# H6 register map
Vendor: Allwinner; Series: H6; File version: 0.1
CPU: CA53 0, little endian, MPU, no FPU, 0 interrupt priority bits
Registers are 32-bit, read-write, reset 0x0 unless marked. A register's access mark holds for its fields unless they carry their own. Offsets are from the block's base; [hi:lo] are bit positions; {n}, {i} and the like mark numbered series.

## OWA
Base 0x05093000
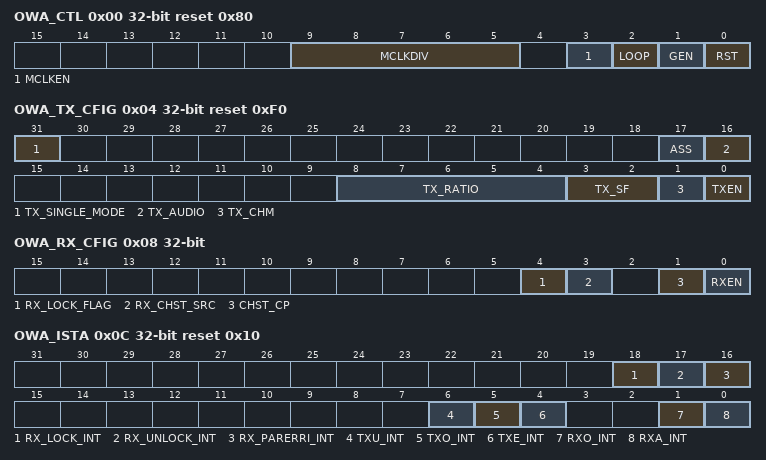
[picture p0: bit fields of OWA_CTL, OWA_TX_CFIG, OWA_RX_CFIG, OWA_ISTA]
0x00 OWA_CTL reset 0x80
  [9:5] MCLKDIV — MCLK Clock Divide Ratio MCLK Divide Ratio from PLL_AUDIO 00000: Divide by 128 00001: Divide by 2 00010: Divide by 4 00011: Divide by 6 00100: Divide by 8 00101: Divide by 10 00110: Divide by 12 00111: Divide by 14 01000: Divide by 16 01001: Divide by 18 01010: Divide by 20 01011: Divide by 22 01100: Divide by 24 ......... 11111: Divide by 62
    0=Divide_by_128; 1=Divide_by_2; 2=Divide_by_4; 3=Divide_by_6; 4=Divide_by_8; 5=Divide_by_10; 6=Divide_by_12; 7=Divide_by_14; 8=Divide_by_16; 9=Divide_by_18; 10=Divide_by_20; 11=Divide_by_22; 12=Divide_by_24; 31=Divide_by_62
  [3] MCLKEN — MCLK Enable 0: Disable 1: Enable
    0=Disable; 1=Enable
  [2] LOOP — Loop Back Test 0: Normal Mode 1: Loop Back Test When set `1`, connecting the DOUT with the DIN.
    0=Normal Mode; 1=Loop Back Test When set `1`, connecting the DOUT with the DIN
  [1] GEN — Global Enable A disable on this bit overrides any other block or channel enables and flushes all FIFOs. 0: Disable 1: Enable
    0=Disable; 1=Enable
  [0] RST — Reset 0: Normal 1: Reset Self clear to 0.
    0=Normal; 1=Reset Self clear to 0
0x04 OWA_TX_CFIG reset 0xF0 — OWA TX Configuration Register
  [31] TX_SINGLE_MODE — Tx Single Channel Mode 0: Disable 1: Enable
    0=Disable; 1=Enable
  [17] ASS — Audio Sample Select with TX FIFO Underrun When 0: Sending 0 1: Sending the last audio This bit is only valid in PCM mode
    0=Sending_0; 1=Sending the last audio This bit is only valid in PCM mode
  [16] TX_AUDIO — TX Data Type 0: Linear PCM (Valid bit of both sub-frame set to 0 ) 1: Non-audio(Valid bit of both sub-frame set to 1)
    0=Linear PCM (Valid bit of both sub-frame set to 0 ); 1=non_audio_openingparen_Valid_bit (Non-audio(Valid bit of both sub-frame set to 1))
  [8:4] TX_RATIO — TX Clock Divide Ratio Clock divide ratio = TX TATIO +1 Fs= PLL_AUDIO/[(TX_TATIO +1)*64*2]
  [3:2] TX_SF — TX Sample Format 00: 16 bits 01: 20 bits 10: 24 bits 11: Reserved
    0=_16_bits; 1=_20_bits; 2=_24_bits
  [1] TX_CHM — CHSTMODE 0: Channel status A&B set to 0 1: Channel status A&B generated form TX_CHSTA
    0=Channel_status_A_amp_B_set (Channel status A&B set to 0); 1=Channel_status_A_amp_B_generated (Channel status A&B generated form TX_CHSTA)
  [0] TXEN — 0: Disabled 1: Enabled
    0=Disabled; 1=Enabled
0x08 OWA_RX_CFIG — OWA RX Configuration Register
  [4] RX_LOCK_FLAG ro — 0: Unlock 1: Lock
    0=Unlock; 1=Lock
  [3] RX_CHST_SRC — 0: RX_CH_STA Register Holds Status from Channel A 1: RX_CH_STA Register Holds Status from Channel B
    0=RX_CH_STA_Register_Holds_Status_from_Channel_A; 1=RX_CH_STA_Register_Holds_Status_from_Channel_B
  [1] CHST_CP — Channel Status Capture 0: Idle or Capture End 1: Capture Channel Status Start When set to `1`, the channel status information is capturing, the bit will clear to `0` after captured.
    0=Idle or Capture End; 1=Capture Channel Status Start When set to `1`, the channel status information is capturing, the bit will clear to `0` after captured
  [0] RXEN — 0: Disabled 1: Enabled
    0=Disabled; 1=Enabled
0x0C OWA_ISTA reset 0x10 — OWA Interrupt Status Register
  [18] RX_LOCK_INT write-1-clears — 0: No Pending IRQ 1: RX lock Pending Interrupt (RX_LOCK_FLAG 0→1) Write `1` to clear this interrupt.
    0=No Pending IRQ; 1=RX (RX lock Pending Interrupt (RX_LOCK_FLAG 0→1) Write `1` to clear this interrupt.)
  [17] RX_UNLOCK_INT write-1-clears — RX Unlock Pending Interrupt 0: No Pending IRQ 1: RX Unlock Pending Interrupt (RX_LOCK_FLAG 1→0) Write `1` to clear this interrupt.
    0=No Pending IRQ; 1=RX (RX Unlock Pending Interrupt (RX_LOCK_FLAG 1→0) Write `1` to clear this interrupt.)
  [16] RX_PARERRI_INT write-1-clears — RX Parity Error Pending Interrupt 0: No Pending IRQ 1: RX Parity Error Pending Interrupt Write `1` to clear this interrupt
    0=No Pending IRQ; 1=RX (RX Parity Error Pending Interrupt Write `1` to clear this interrupt)
  [6] TXU_INT — TX FIFO Underrun Pending Interrupt 0: No Pending IRQ 1: FIFO Underrun Pending Interrupt Writing `1` to clear this interrupt.
    0=No Pending IRQ; 1=FIFO (FIFO Underrun Pending Interrupt Writing `1` to clear this interrupt.)
  [5] TXO_INT — TX FIFO Overrun Pending Interrupt 0: No Pending IRQ 1: FIFO Overrun Pending Interrupt Writing `1` to clear this interrupt.
    0=No Pending IRQ; 1=FIFO (FIFO Overrun Pending Interrupt Writing `1` to clear this interrupt.)
  [4] TXE_INT — TX FIFO Empty Pending Interrupt 0: No Pending IRQ 1: FIFO Empty Pending Interrupt Writing `1` to clear this interrupt or automatically clear if the interrupt condition fails.
    0=No Pending IRQ; 1=FIFO (FIFO Empty Pending Interrupt Writing `1` to clear this interrupt or automatically clear if the interrupt condition fails.)
  [1] RXO_INT write-1-clears — RXFIFO Overrun Pending Interrupt 0: RXFIFO Overrun Pending Write `1` to clear this interrupt.
    0=RXFIFO (RXFIFO Overrun Pending Write `1` to clear this interrupt.)
  [0] RXA_INT write-1-clears — RXFIFO Available Pending Interrupt 0: No Pending IRQ 1: Data Available Pending IRQ Write `1` to clear this interrupt or automatically clear if interrupt condition fails.
    0=No Pending IRQ; 1=Data Available Pending IRQ Write `1` to clear this interrupt or automatically clear if interrupt condition fails
0x10 OWA_RXFIFO
  [31:0] RX_DATA ro — Host can get one sample by reading this register, the A channel data is first and then the B channel data.
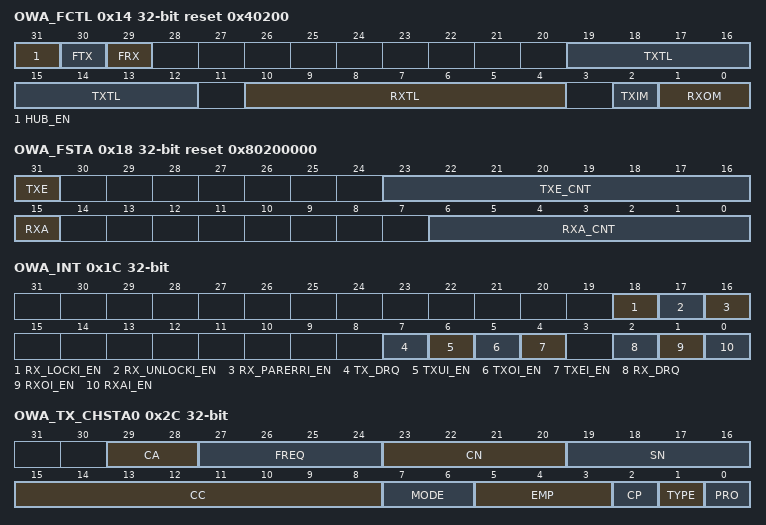
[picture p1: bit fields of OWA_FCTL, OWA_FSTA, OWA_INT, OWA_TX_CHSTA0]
0x14 OWA_FCTL reset 0x40200 — OWA FIFO Control Register
  [31] HUB_EN — Audio Hub Enable 0: Disable 1: Enable
    0=Disable; 1=Enable
  [30] FTX write-1-clears — Write `1` to flush TXFIFO, self clear to `0`.
  [29] FRX write-1-clears — Write `1` to flush RXFIFO, self clear to `0`.
  [19:12] TXTL — TX FIFO empty Trigger Level Interrupt and DMA request trigger level for TX FIFO normal condition. Trigger Level = TXTL
  [10:4] RXTL — RX FIFO Trigger Level Interrupt and DMA request trigger level for RX FIFO normal condition. Trigger Level = RXTL + 1
  [2] TXIM — TXFIFO Input Mode(Mode0, 1) 0: Valid Data at the MSB of TXFIFO Register 1: Valid Data at the LSB of TXFIFO Register Example for 20-bits transmitted audio sample: Mode 0: TXFIFO[23:0] = {APB_WDATA[31:12], 4`h0} Mode 1: TXFIFO[23:0] = {APB_WDATA[19:0], 4`h0}
    0=Valid Data at the MSB of TXFIFO Register; 1=Valid Data at the LSB of TXFIFO Register Example for 20-bits transmitted audio sample: Mode 0: TXFIFO[23:0] = {APB_WDATA[31:12], 4`h0} Mode 1: TXFIFO[23:0] = {APB_WDATA[19:0], 4`h0}
  [1:0] RXOM — RXFIFO Output Mode(Mode 0,1,2,3) 00: Expanding `0` at LSB of RXFIFO Register 01: Expanding Received Sample Sign bit at MSB of RXFIFO Register 10: Truncating Received Samples at High Half-word of RXFIFO Register and Low Half-word of RXFIFO Register is filled by `0` 11: Truncating Received Samples at Low Half-word of RXFIFO Register and High Half-word of RXFIFO Register is Expanded by Its Sigh Bit Mode 0: APB_RDATA[31:0] = {RXFIFO[23:0], 8`h0} Mode 1: APB_RDATA[31:0] = {8`RXFIFO[23], RXFIFO[23:0]} Mode 2: APB_RDATA[31:0] = {RXFIFO[23:8], 16`h0} Mode 3: APB_RDATA[31:0] ={16`RXFIFO[23], RXFIFO[23:8]}
    0=Expanding `0` at LSB of RXFIFO Register; 1=Expanding Received Sample Sign bit at MSB of RXFIFO Register; 2=Truncating Received Samples at High Half-word of RXFIFO Register and Low Half-word of RXFIFO Register is filled by `0`; 3=Truncating Received Samples at Low Half-word of RXFIFO Register and High Half-word of RXFIFO Register is Expanded by Its Sigh Bit Mode 0: APB_RDATA[31:0] = {RXFIFO[23:0], 8`h0} Mode 1: APB_RDATA[31:0] = {8`RXFIFO[23], RXFIFO[23:0]} Mode 2: APB_RDATA[31:0] = {RXFIFO[23:8], 16`h0} Mode 3: APB_RDATA[31:0] ={16`RXFIFO[23], RXFIFO[23:8]}
0x18 OWA_FSTA reset 0x80200000 — OWA FIFO Status Register
  [31] TXE ro — TXFIFO Empty (Indicate TXFIFO is Not Full) 0: No Room for New Sample in TXFIFO 1: More than One Room for New Sample in TXFIFO ( >=1 Word )
    0=No Room for New Sample in TXFIFO; 1=More than One Room for New Sample in TXFIFO ( >=1 Word )
  [23:16] TXE_CNT ro — TXFIFO Empty Space Word Counter
  [15] RXA ro — RXFIFO Available 0: No Available Data in RXFIFO 1: More than One Sample in RXFIFO ( >=1 Word )
    0=No Available Data in RXFIFO; 1=More than One Sample in RXFIFO ( >=1 Word )
  [6:0] RXA_CNT ro — RXFIFO Available Sample Word Counter
0x1C OWA_INT — OWA Interrupt Control Register
  [all] fields
    0=Disable; 1=Enable
  [18] RX_LOCKI_EN — RX LOCK Interrupt Enable 0: Disable 1: Enable
  [17] RX_UNLOCKI_EN — RX UNLOCK Interrupt Enable 0: Disable 1: Enable
  [16] RX_PARERRI_EN — RX PARITY ERORR Interrupt Enable 0: Disable 1: Enable
  [7] TX_DRQ — TXFIFO Empty DRQ Enable 0: Disable 1: Enable
  [6] TXUI_EN — TXFIFO Underrun Interrupt Enable 0: Disable 1: Enable
  [5] TXOI_EN — TXFIFO Overrun Interrupt Enable 0: Disable 1: Enable
  [4] TXEI_EN — TXFIFO Empty Interrupt Enable 0: Disable 1: Enable
  [2] RX_DRQ — RXFIFO Data Available DRQ Enable When Set to `1`, RXFIFO DMA Request is Asserted if Data is Available in RXFIFO. 0: Disable 1: Enable
  [1] RXOI_EN — RXFIFO Overrun Interrupt Enable 0: Disable 1: Enable
  [0] RXAI_EN — RXFIFO Data Available Interrupt Enable 0: Disable 1: Enable
0x20 OWA_TXFIFO
  [31:0] TX_DATA wo — Transmitting A, B channel data should be written this register one by one. The A channel data is first and then the B channel data.
0x24 OWA_TX_CNT — OWA TX Counter Register
  [31:0] TX_CNT — TX Sample Counter The audio sample number of sending into TXFIFO. When one sample is put into TXFIFO by DMA or by host IO, the TX sample counter register increases by one. The TX sample counter register can be set to any initial value at any time. After updated by the initial value, the counter register should count on base of this initial value.
0x28 OWA_RX_CNT — OWA RX Counter Register
  [31:0] RX_CNT — RX Sample Counter The audio sample number of writing into RXFIFO. When one sample is written by Codec, the RX sample counter register increases by one. The RX Counter register can be set to any initial value at any time. After been updated by the initial value, the counter register should count on base of this value.
0x2C OWA_TX_CHSTA0 — OWA TX Channel Status Register0
  [29:28] CA — Clock Accuracy 00: Level 2 01: Level 1 10: Level 3 11: Not matched
    0=Level_2; 1=Level_1; 2=Level_3; 3=Not_matched
  [27:24] FREQ — Sampling Frequency 0000: 44.1kHz 0001: Not indicated 0010: 48kHz 0011: 32kHz 0100: 22.05kHz 0101: Reserved 0110: 24kHz 0111: Reserved 1000: Reserved 1001: 768kHz 1010: 96kHz 1011: Reserved 1100:176.4kHz 1101: Reserved 1110: 192kHz 1111: Reserved
    0=_44_point_1kHz (44.1kHz); 1=Not_indicated; 2=_48kHz; 3=_32kHz; 4=_22_point_05kHz (22.05kHz); 6=_24kHz; 9=_768kHz; 10=_96kHz; 14=_192kHz
  [23:20] CN — Channel Number
  [19:16] SN — Source Number
  [15:8] CC — Category Code Indicates the kind of equipment that generates the digital audio interface signal.
  [7:6] MODE — Mode 00: Default Mode 01~11: Reserved
    0=Default Mode 01~11: Reserved
  [5:3] EMP — Emphasis Additional format information For bit 1 = `0`, Linear PCM audio mode: 000: 2 audio channels without pre-emphasis 001: 2 audio channels with 50 μs / 15 μs pre-emphasis 010: Reserved (for 2 audio channels with pre-emphasis) 011: Reserved (for 2 audio channels with pre-emphasis) 100~111: Reserved For bit 1 = `1`, other than Linear PCM applications: 000: Default state 001~111: Reserved
  [2] CP — Copyright 0: Copyright is asserted 1: No copyright is asserted
    0=Copyright is asserted; 1=No copyright is asserted
  [1] TYPE — Audio Data Type 0: Linear PCM Samples 1: For none-linear PCM audio such as AC3, DTS, MPEG audio
    0=Linear PCM Samples; 1=For (For none-linear PCM audio such as AC3, DTS, MPEG audio)
  [0] PRO — Application Type 0: Consumer Application 1: Professional Application This bit must be fixed to `0`
    0=Consumer Application; 1=Professional Application This bit must be fixed to `0`
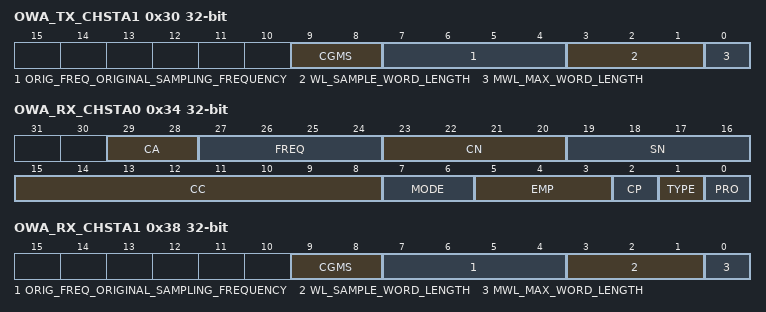
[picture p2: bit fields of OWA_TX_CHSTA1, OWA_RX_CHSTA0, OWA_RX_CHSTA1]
0x30 OWA_TX_CHSTA1 — OWA TX Channel Status Register1
  [9:8] CGMS — CGMS_A 00: Copying is permitted without restriction 01: One generation of copies may be made 10: Condition not be used 11: No copying is permitted
    0=Copying is permitted without restriction; 1=One (One generation of copies may be made); 2=Condition not be used; 3=No copying is permitted
  [7:4] ORIG_FREQ_ORIGINAL_SAMPLING_FREQUENCY — ORIG_FREQ Original Sampling Frequency 0000: Not indicated 0001: 192kHz 0010: 12kHz 0011: 176.4kHz 0100: Reserved 0101: 96kHz 0110: 8kHz 0111: 88.2kHz 1000: 16kHz 1001: 24kHz 1010: 11.025kHz 1011: 22.05kHz 1100: 32kHz 1101: 48kHz 1110: Reserved 1111: 44.1kHz
    0=Not_indicated; 1=_192kHz; 2=_12kHz; 3=_176_point_4kHz (176.4kHz); 5=_96kHz; 6=_8kHz; 7=_88_point_2kHz (88.2kHz); 8=_16kHz; 9=_24kHz; 10=_11_point_025kHz (11.025kHz); 11=_22_point_05kHz (22.05kHz); 12=_32kHz; 13=_48kHz; 15=_44_point_1kHz (44.1kHz)
  [3:1] WL_SAMPLE_WORD_LENGTH — WL Sample Word Length For bit 0 = `0`: 000: Not indicated 001: 16 bits 010: 18 bits 100: 19 bits 101: 20 bits 110: 17 bits 111: Reserved For bit 0 = `1`: 000: Not indicated 001: 20 bits 010: 22 bits 100: 23 bits 101: 24 bits 110: 21 bits 111: Reserved
  [0] MWL_MAX_WORD_LENGTH — MWL Max Word Length 0: Maximum audio sample word length is 20 bits 1: Maximum audio sample word length is 24 bits
    0=Maximum audio sample word length is 20 bits; 1=Maximum audio sample word length is 24 bits
0x34 OWA_RX_CHSTA0
  [29:28] CA — Clock Accuracy 00: Level 2 01: Level 1 10: Level 3 11: Not Matched
    0=Level_2; 1=Level_1; 2=Level_3; 3=Not_Matched
  [27:24] FREQ — Sampling Frequency 0000: 44.1kHz 0001: Not Indicated 0010: 48kHz 0011: 32kHz 0100: 22.05kHz 0101: Reserved 0110: 24kHz 0111: Reserved 1000: Reserved 1001: 768kHz 1010: 96kHz 1011: Reserved 1100:176.4kHz 1101: Reserved 1110: 192kHz 1111: Reserved
    0=_44_point_1kHz (44.1kHz); 1=Not_Indicated; 2=_48kHz; 3=_32kHz; 4=_22_point_05kHz (22.05kHz); 6=_24kHz; 9=_768kHz; 10=_96kHz; 14=_192kHz
  [23:20] CN — Channel Number
  [19:16] SN — Source Number
  [15:8] CC — Category Code Indicates the Kind of Equipment that Generates the digital audio interface Signal.
  [7:6] MODE — Mode 00: Default Mode 01~11: Reserved
    0=Default Mode 01~11: Reserved
  [5:3] EMP — Emphasis Additional Format Information For bit 1 = `0`, Linear PCM Audio Mode: 000: 2 Audio Channels without Pre-emphasis 001: 2 Audio Channels with 50 μs / 15 μs Pre-emphasis 010: Reserved (For 2 Audio Channels with Pre-emphasis) 011: Reserved (For 2 Audio Channels with Pre-emphasis) 100~111: Reserved For bit 1 = `1`, Other than Linear PCM Applications: 000: Default State 001~111: Reserved
  [2] CP — Copyright 0: Copyright is Asserted 1: No Copyright is Asserted
    0=Copyright is Asserted; 1=No Copyright is Asserted
  [1] TYPE — Audio Data Type 0: Linear PCM Samples 1: For None-linear PCM Audio Such as AC3, DTS, MPEG Audio
    0=Linear PCM Samples; 1=For (For None-linear PCM Audio Such as AC3, DTS, MPEG Audio)
  [0] PRO — Application Type 0: Consumer Application 1: Professional Application
    0=Consumer Application; 1=Professional Application
0x38 OWA_RX_CHSTA1
  [9:8] CGMS — CGMS_A 00: Copying is Permitted without Restriction 01: One Generation of Copies May Be Made 10: Condition Not Be Used 11: No Copying is Permitted
    0=Copying is Permitted without Restriction; 1=One (One Generation of Copies May Be Made); 2=Condition Not Be Used; 3=No Copying is Permitted
  [7:4] ORIG_FREQ_ORIGINAL_SAMPLING_FREQUENCY — ORIG_FREQ Original Sampling Frequency 0000: Not Indicated 0001: 192kHz 0010: 12kHz 0011: 176.4kHz 0100: Reserved 0101: 96kHz 0110: 8kHz 0111: 88.2kHz 1000: 16kHz 1001: 24kHz 1010: 11.025kHz 1011: 22.05kHz 1100: 32kHz 1101: 48kHz 1110: Reserved 1111: 44.1kHz
    0=Not_Indicated; 1=_192kHz; 2=_12kHz; 3=_176_point_4kHz (176.4kHz); 5=_96kHz; 6=_8kHz; 7=_88_point_2kHz (88.2kHz); 8=_16kHz; 9=_24kHz; 10=_11_point_025kHz (11.025kHz); 11=_22_point_05kHz (22.05kHz); 12=_32kHz; 13=_48kHz; 15=_44_point_1kHz (44.1kHz)
  [3:1] WL_SAMPLE_WORD_LENGTH — WL Sample Word Length For bit 0 = `0`: 000: Not Indicated 001: 16 bits 010: 18 bits 100: 19 bits 101: 20 bits 110: 17 bits 111: Reserved For bit 0 = `1`: 000: Not Indicated 001: 20 bits 010: 22 bits 100: 23 bits 101: 24 bits 110: 21 bits 111: Reserved
  [0] MWL_MAX_WORD_LENGTH — MWL Max Word Length 0: Maximum Audio Sample Word Length is 20 bits 1: Maximum Audio Sample Word Length is 24 bits
    0=Maximum Audio Sample Word Length is 20 bits; 1=Maximum Audio Sample Word Length is 24 bits
